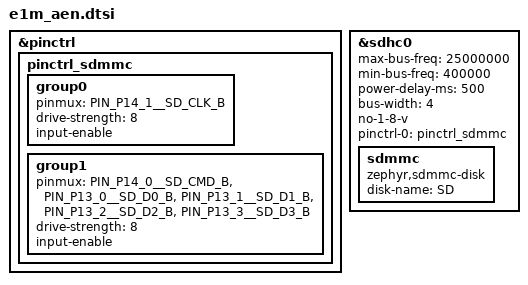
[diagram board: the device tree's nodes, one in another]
/*
 * Copyright (c) 2026 Alp Lab AB
 * SPDX-License-Identifier: Apache-2.0
 *
 * e1m_evk_microsd on the E1M-AEN SoMs (Alif Ensemble E4 / E8): sdhc0 on the
 * SD "B" pads -- CLK P14_1, CMD P14_0, D0..D3 P13_0..P13_3
 * (metadata/pinmux/aen.yaml).
 *
 * Silicon (E1M-EVK 2626-R2, reworked mux, card in J7, 4-bit, 25 MHz):
 * E1M-AEN803 M55-HE 2026-09-15 and E1M-AEN401 M55-HP 2026-10-12 read sector
 * 0 and moved FatFs/exFAT files with these settings. One E1M-AEN801 unit
 * (2026W36-0008) on another carrier fails CMD55/ACMD51 at 25 MHz with
 * ERROR_INT_STAT 0x000a and works at 10 MHz; lower max-bus-freq in an app
 * overlay if a board shows that error.
 *
 * The ADMA engine cannot reach the M55 TCMs; CONFIG_SDHC_DWC_BOUNCE_BUFFER
 * (default on Ensemble) copies through SRAM0, so apps keep their normal
 * DTCM-linked RAM.
 */

#include <zephyr/dt-bindings/pinctrl/alif-ensemble-pinctrl.h>

&pinctrl {
	pinctrl_sdmmc: pinctrl_sdmmc {
		group0 {
			pinmux = <PIN_P14_1__SD_CLK_B>;
			drive-strength = <8>;
			input-enable;
		};
		group1 {
			pinmux = <PIN_P14_0__SD_CMD_B>,
				 <PIN_P13_0__SD_D0_B>, <PIN_P13_1__SD_D1_B>,
				 <PIN_P13_2__SD_D2_B>, <PIN_P13_3__SD_D3_B>;
			drive-strength = <8>;
			input-enable;
		};
	};
};

&sdhc0 {
	max-bus-freq = <25000000>;
	min-bus-freq = <400000>;
	power-delay-ms = <500>;
	bus-width = <4>;
	no-1-8-v;
	pinctrl-0 = <&pinctrl_sdmmc>;
	pinctrl-names = "default";
	status = "okay";

	sdmmc {
		compatible = "zephyr,sdmmc-disk";
		disk-name = "SD";
		status = "okay";
	};
};
